# STM32F746xx register map
File version: 1.0
Registers are 32-bit, access not given, reset 0x0 unless marked. A register's access mark holds for its fields unless they carry their own. Offsets are from the block's base; [hi:lo] are bit positions; {n}, {i} and the like mark numbered series.

## SAI1
Base 0x40015800
Same registers: SAI2 0x40015C00
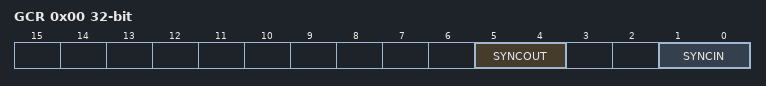
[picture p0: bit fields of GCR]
0x00 GCR
  [5:4] SYNCOUT, [1:0] SYNCIN
0x04 CR1A
0x08 CR2A
0x10 FRCRA
0x1C SLOTRA
0x24 CR1B
0x28 CR2B
0x2C IMRA
0x30 FRCRB
0x3C SLOTRB
0x40 SRA
0x4C IMRB
0x58 CLRFRA
0x60 SRB
0x74 DRA
0x78 CLRFRB
0x94 DRB

## LTDC
Base 0x40016800
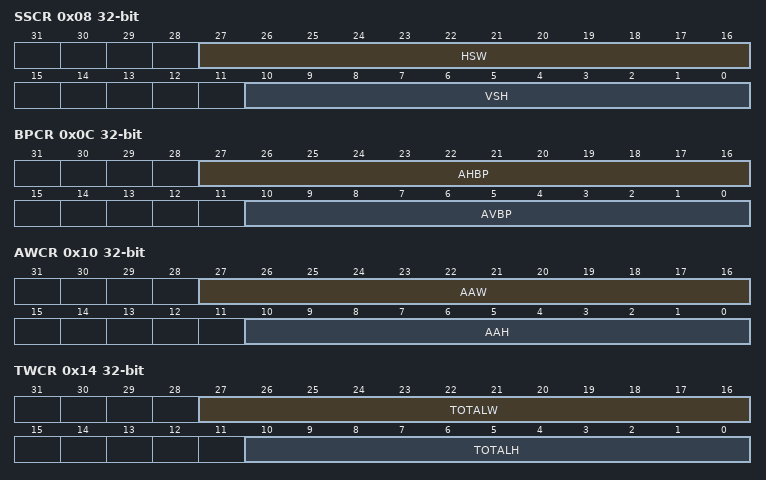
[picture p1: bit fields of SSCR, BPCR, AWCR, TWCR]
0x08 SSCR
  [27:16] HSW, [10:0] VSH
0x0C BPCR
  [27:16] AHBP, [10:0] AVBP
0x10 AWCR
  [27:16] AAW, [10:0] AAH
0x14 TWCR
  [27:16] TOTALW, [10:0] TOTALH
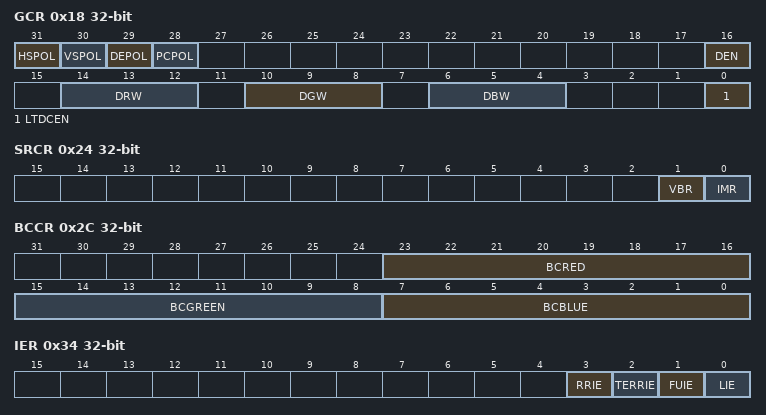
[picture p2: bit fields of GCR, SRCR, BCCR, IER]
0x18 GCR
  [31] HSPOL, [30] VSPOL, [29] DEPOL, [28] PCPOL, [16] DEN, [14:12] DRW, [10:8] DGW, [6:4] DBW, [0] LTDCEN
0x24 SRCR
  [1] VBR, [0] IMR
0x2C BCCR
  [23:16] BCRED, [15:8] BCGREEN, [7:0] BCBLUE
0x34 IER
  [3] RRIE, [2] TERRIE, [1] FUIE, [0] LIE
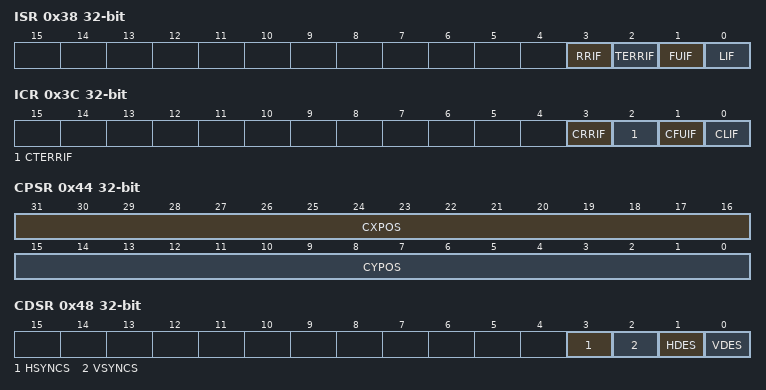
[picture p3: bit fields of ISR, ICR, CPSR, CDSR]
0x38 ISR
  [3] RRIF, [2] TERRIF, [1] FUIF, [0] LIF
0x3C ICR
  [3] CRRIF, [2] CTERRIF, [1] CFUIF, [0] CLIF
0x40 LIPCR
  [10:0] LIPOS
0x44 CPSR
  [31:16] CXPOS, [15:0] CYPOS
0x48 CDSR
  [3] HSYNCS, [2] VSYNCS, [1] HDES, [0] VDES
0x84 CR1
0x88 WHPCR1
0x90 WVPCR1
0x9C CKCR1
0xAC PFCR1
0xC0 CACR1
0xD8 DCCR1
0xF4 BFCR1
0x104 CR2
0x108 WHPCR2
0x110 WVPCR2
0x11C CFBAR1
0x11C CKCR2
0x12C PFCR2
0x140 CACR2
0x148 CFBLR1
0x158 DCCR2
0x174 BFCR2
0x178 CFBLNR1
0x19C CFBAR2
0x1B8 CLUTWR1
0x1C8 CFBLR2
0x1F8 CFBLNR2
0x238 CLUTWR2

## GPIOA
Base 0x40020000
Same registers: GPIOB 0x40020400, GPIOC 0x40020800, GPIOD 0x40020C00, GPIOE 0x40021000, GPIOF 0x40021400, GPIOG 0x40021800, GPIOH 0x40021C00, GPIOI 0x40022000, GPIOJ 0x40022400, GPIOK 0x40022800
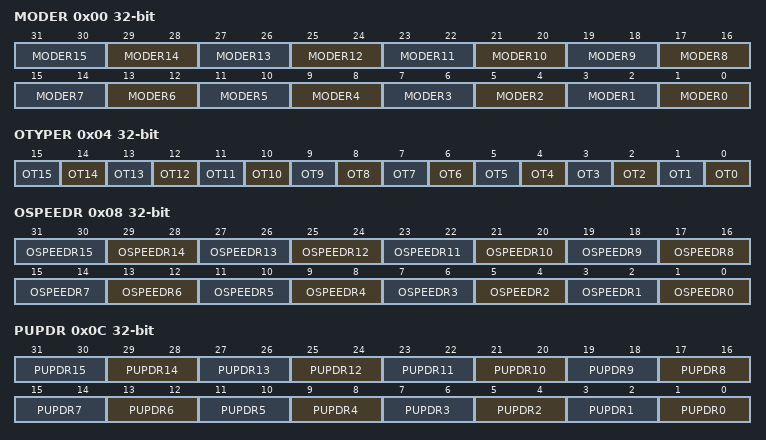
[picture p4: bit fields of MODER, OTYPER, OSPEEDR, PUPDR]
0x00 MODER
  [2n+1:2n] MODER{n} (n=0..15)
0x04 OTYPER
  [n] OT{n} (n=0..15)
0x08 OSPEEDR
  [2n+1:2n] OSPEEDR{n} (n=0..15)
0x0C PUPDR
  [2n+1:2n] PUPDR{n} (n=0..15)
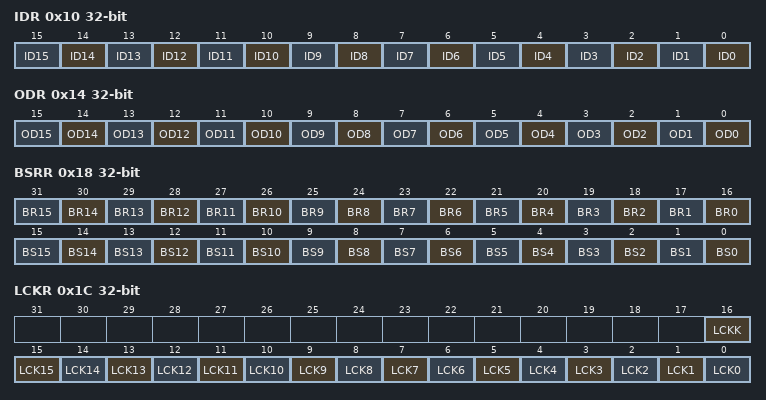
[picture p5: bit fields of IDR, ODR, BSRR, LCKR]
0x10 IDR
  [n] ID{n} (n=0..15)
0x14 ODR
  [n] OD{n} (n=0..15)
0x18 BSRR
  [n+16] BR{n} (n=0..15), [n] BS{n} (n=0..15)
0x1C LCKR
  [16] LCKK, [n] LCK{n} (n=0..15)
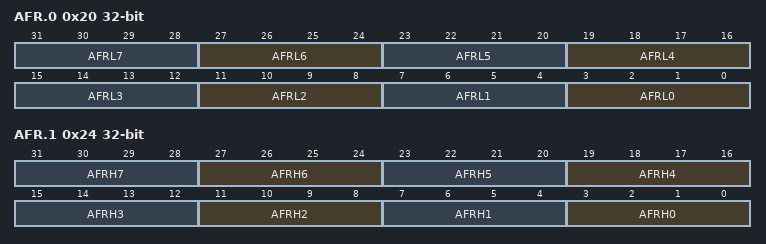
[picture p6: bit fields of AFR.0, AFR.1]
0x20 AFR.0
  [4n+3:4n] AFRL{n} (n=0..7)
0x24 AFR.1
  [4n+3:4n] AFRH{n} (n=0..7)

## CRC
Base 0x40023000
0x00 DR
0x04 IDR 8-bit
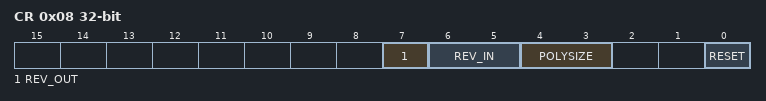
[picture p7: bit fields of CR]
0x08 CR
  [7] REV_OUT, [6:5] REV_IN, [4:3] POLYSIZE, [0] RESET
0x10 INIT
0x14 POL

## FLASH
Base 0x40023C00
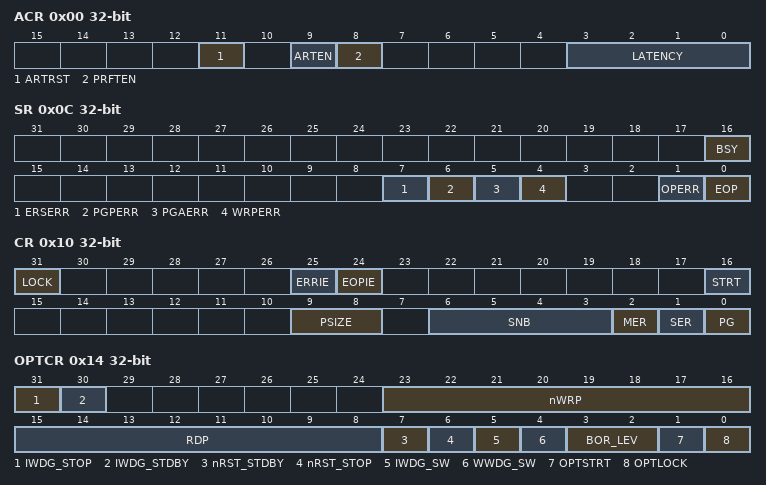
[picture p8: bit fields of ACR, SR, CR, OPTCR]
0x00 ACR
  [11] ARTRST, [9] ARTEN, [8] PRFTEN, [3:0] LATENCY
0x04 KEYR
0x08 OPTKEYR
0x0C SR
  [16] BSY, [7] ERSERR, [6] PGPERR, [5] PGAERR, [4] WRPERR, [1] OPERR, [0] EOP
0x10 CR
  [31] LOCK, [25] ERRIE, [24] EOPIE, [16] STRT, [9:8] PSIZE, [6:3] SNB, [2] MER, [1] SER, [0] PG
0x14 OPTCR
  [31] IWDG_STOP, [30] IWDG_STDBY, [23:16] nWRP, [15:8] RDP, [7] nRST_STDBY, [6] nRST_STOP, [5] IWDG_SW, [4] WWDG_SW, [3:2] BOR_LEV, [1] OPTSTRT, [0] OPTLOCK
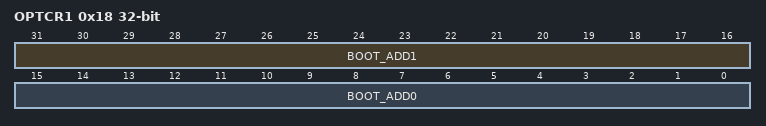
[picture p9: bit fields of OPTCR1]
0x18 OPTCR1
  [31:16] BOOT_ADD1, [15:0] BOOT_ADD0

## DMA1
Base 0x40026000
Same registers: DMA2 0x40026400
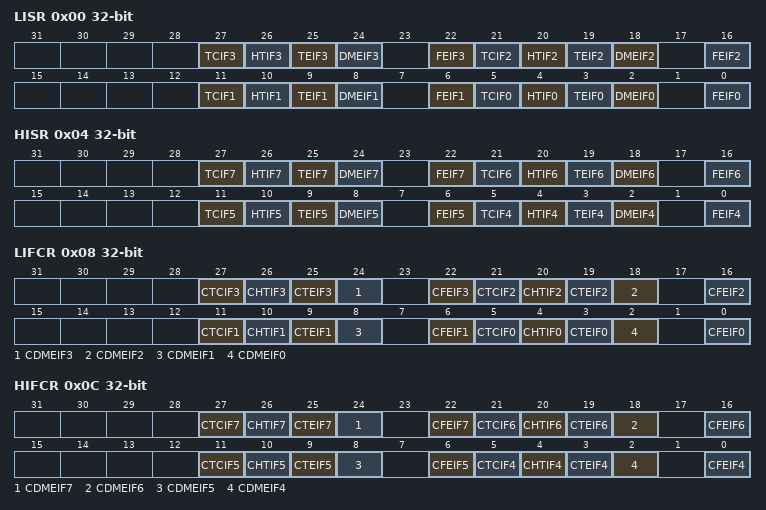
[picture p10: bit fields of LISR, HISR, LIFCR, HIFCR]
0x00 LISR
  [27] TCIF3, [26] HTIF3, [25] TEIF3, [24] DMEIF3, [22] FEIF3, [21] TCIF2, [20] HTIF2, [19] TEIF2, [18] DMEIF2, [16] FEIF2, [11] TCIF1, [10] HTIF1, [9] TEIF1, [8] DMEIF1, [6] FEIF1, [5] TCIF0, [4] HTIF0, [3] TEIF0, [2] DMEIF0, [0] FEIF0
0x04 HISR
  [27] TCIF7, [26] HTIF7, [25] TEIF7, [24] DMEIF7, [22] FEIF7, [21] TCIF6, [20] HTIF6, [19] TEIF6, [18] DMEIF6, [16] FEIF6, [11] TCIF5, [10] HTIF5, [9] TEIF5, [8] DMEIF5, [6] FEIF5, [5] TCIF4, [4] HTIF4, [3] TEIF4, [2] DMEIF4, [0] FEIF4
0x08 LIFCR
  [27] CTCIF3, [26] CHTIF3, [25] CTEIF3, [24] CDMEIF3, [22] CFEIF3, [21] CTCIF2, [20] CHTIF2, [19] CTEIF2, [18] CDMEIF2, [16] CFEIF2, [11] CTCIF1, [10] CHTIF1, [9] CTEIF1, [8] CDMEIF1, [6] CFEIF1, [5] CTCIF0, [4] CHTIF0, [3] CTEIF0, [2] CDMEIF0, [0] CFEIF0
0x0C HIFCR
  [27] CTCIF7, [26] CHTIF7, [25] CTEIF7, [24] CDMEIF7, [22] CFEIF7, [21] CTCIF6, [20] CHTIF6, [19] CTEIF6, [18] CDMEIF6, [16] CFEIF6, [11] CTCIF5, [10] CHTIF5, [9] CTEIF5, [8] CDMEIF5, [6] CFEIF5, [5] CTCIF4, [4] CHTIF4, [3] CTEIF4, [2] CDMEIF4, [0] CFEIF4
{0x10+0x18*i} CR{i} (i=0..7)
{0x14+0x18*i} NDTR{i} (i=0..7)
{0x1C+0x18*i} PAR{i} (i=0..7)
{0x28+0x18*i} M0AR{i} (i=0..7)
{0x38+0x18*i} M1AR{i} (i=0..7)
{0x4C+0x18*i} FCR{i} (i=0..7)
